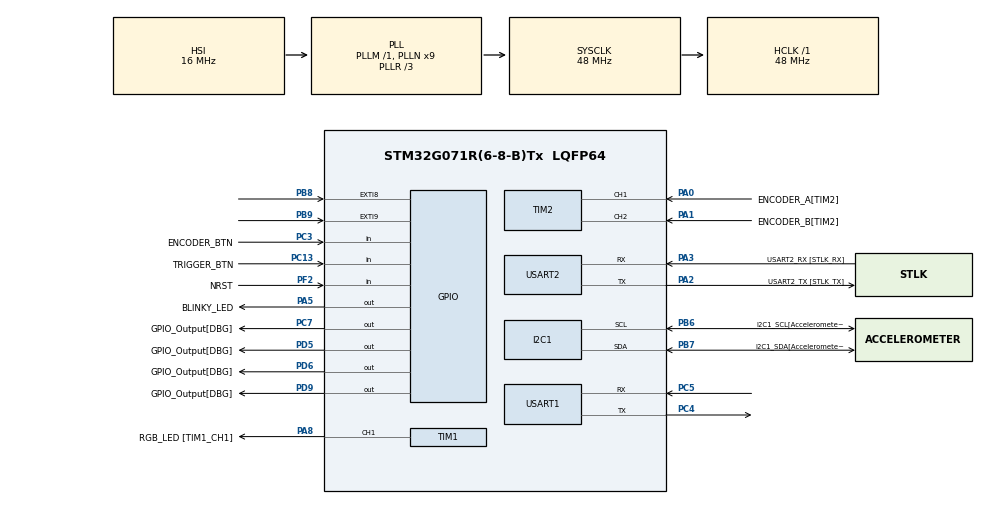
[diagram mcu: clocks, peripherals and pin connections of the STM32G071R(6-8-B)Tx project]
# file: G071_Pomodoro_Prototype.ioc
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Dma.Request0=TIM1_CH1
Dma.TIM1_CH1.0.Direction=DMA_MEMORY_TO_PERIPH
Dma.TIM1_CH1.0.EventEnable=DISABLE
Dma.TIM1_CH1.0.Instance=DMA1_Channel1
Dma.TIM1_CH1.0.MemDataAlignment=DMA_MDATAALIGN_HALFWORD
Dma.TIM1_CH1.0.MemInc=DMA_MINC_ENABLE
Dma.TIM1_CH1.0.Mode=DMA_NORMAL
Dma.TIM1_CH1.0.PeriphDataAlignment=DMA_PDATAALIGN_HALFWORD
Dma.TIM1_CH1.0.PeriphInc=DMA_PINC_DISABLE
Dma.TIM1_CH1.0.Polarity=HAL_DMAMUX_REQ_GEN_RISING
Dma.TIM1_CH1.0.Priority=DMA_PRIORITY_LOW
Dma.TIM1_CH1.0.RequestNumber=1
Dma.TIM1_CH1.0.SignalID=NONE
Dma.TIM1_CH1.0.SyncEnable=DISABLE
Dma.TIM1_CH1.0.SyncPolarity=HAL_DMAMUX_SYNC_NO_EVENT
Dma.TIM1_CH1.0.SyncRequestNumber=1
Dma.TIM1_CH1.0.SyncSignalID=NONE
I2C1.Timing=0x20303E5D
IWDG.Prescaler=IWDG_PRESCALER_32
Mcu.Family=STM32G0
Mcu.Name=STM32G071R(6-8-B)Tx
Mcu.Package=LQFP64
NVIC.DMA1_Channel1_IRQn=true\:0\:0\:false\:false\:true\:false\:true\:true
NVIC.TIM14_IRQn=true\:0\:0\:false\:false\:true\:true\:true\:true
PA0.GPIO_Label=ENCODER_A[TIM2]
PA0.Signal=S_TIM2_CH1_ETR
PA1.GPIO_Label=ENCODER_B[TIM2]
PA1.Signal=S_TIM2_CH2
PA13.GPIO_Label=SWDIO
PA13.Mode=Serial_Wire
PA13.Signal=SYS_SWDIO
PA14-BOOT0.GPIO_Label=SWCLK
PA14-BOOT0.Mode=Serial_Wire
PA14-BOOT0.Signal=SYS_SWCLK
PA2.GPIO_Label=USART2_TX [STLK_TX]
PA2.GPIO_PuPd=GPIO_PULLUP
PA2.Mode=Asynchronous
PA2.Signal=USART2_TX
PA3.GPIO_Label=USART2_RX [STLK_RX]
PA3.GPIO_PuPd=GPIO_PULLUP
PA3.Mode=Asynchronous
PA3.Signal=USART2_RX
PA5.GPIO_Label=BLINKY_LED
PA5.GPIO_Speed=GPIO_SPEED_FREQ_HIGH
PA5.Signal=GPIO_Output
PA8.GPIO_Label=RGB_LED [TIM1_CH1]
PA8.Signal=S_TIM1_CH1
PB6.GPIO_Label=I2C1_SCL[Accelerometer]
PB6.Mode=I2C
PB6.Signal=I2C1_SCL
PB7.GPIO_Label=I2C1_SDA[Accelerometer]
PB7.Mode=I2C
PB7.Signal=I2C1_SDA
PB8.Signal=GPXTI8
PB9.Signal=GPXTI9
PC13.GPIO_Label=TRIGGER_BTN
PC13.GPIO_PuPd=GPIO_PULLUP
PC13.Signal=GPIO_Input
PC3.GPIO_Label=ENCODER_BTN
PC3.GPIO_PuPd=GPIO_PULLUP
PC3.Signal=GPIO_Input
PC4.Mode=Asynchronous
PC4.Signal=USART1_TX
PC5.Mode=Asynchronous
PC5.Signal=USART1_RX
PC7.GPIO_Label=GPIO_Output[DBG]
PC7.Signal=GPIO_Output
PD5.GPIO_Label=GPIO_Output[DBG]
PD5.Signal=GPIO_Output
PD6.GPIO_Label=GPIO_Output[DBG]
PD6.Signal=GPIO_Output
PD9.GPIO_Label=GPIO_Output[DBG]
PD9.Signal=GPIO_Output
PF2\ -\ NRST.GPIO_Label=NRST
PF2\ -\ NRST.GPIO_PuPd=GPIO_PULLUP
PF2\ -\ NRST.Signal=GPIO_Input
ProjectManager.HeapSize=0x200
ProjectManager.StackSize=0x400
ProjectManager.TargetToolchain=STM32CubeIDE
RCC.ADCFreq_Value=48000000
RCC.AHBFreq_Value=48000000
RCC.CortexFreq_Value=48000000
RCC.EXTERNAL_CLOCK_VALUE=12288000
RCC.HCLKFreq_Value=48000000
RCC.HSE_VALUE=8000000
RCC.HSI_VALUE=16000000
RCC.LSE_VALUE=32768
RCC.PLLN=9
RCC.PLLR=RCC_PLLR_DIV3
RCC.SYSCLKFreq_VALUE=48000000
RCC.SYSCLKSource=RCC_SYSCLKSOURCE_PLLCLK
RCC.VCOOutputFreq_Value=144000000
RTC.Date=31
RTC.Hours=23
RTC.Minutes=59
RTC.Month=RTC_MONTH_DECEMBER
RTC.Seconds=40
SH.S_TIM1_CH1.0=TIM1_CH1,PWM Generation1 CH1
SH.S_TIM2_CH1_ETR.0=TIM2_CH1,Encoder_Interface
SH.S_TIM2_CH2.0=TIM2_CH2,Encoder_Interface
TIM1.Channel-PWM\ Generation1\ CH1=TIM_CHANNEL_1
TIM1.Period=60-1
TIM1.Prescaler=0
TIM14.Period=1000-1
TIM14.Prescaler=48-1
USART1.VirtualMode-Asynchronous=VM_ASYNC
USART2.VirtualMode-Asynchronous=VM_ASYNC
VP_IWDG_VS_IWDG.Mode=IWDG_Activate
VP_RTC_VS_RTC_Activate.Mode=RTC_Enabled
VP_RTC_VS_RTC_Calendar.Mode=RTC_Calendar
VP_SYS_VS_DBSignals.Mode=DisableDeadBatterySignals
VP_TIM14_VS_ClockSourceINT.Mode=Enable_Timer
VP_TIM1_VS_ClockSourceINT.Mode=Internal
board=NUCLEO-G071RB

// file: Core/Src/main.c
/* USER CODE BEGIN Header */
/**
 ******************************************************************************
 * @file           : main.c
 * @brief          : Main program body
 ******************************************************************************
 * @attention
 *
 * Copyright (c) 2023 STMicroelectronics.
 * All rights reserved.
 *
 * This software is licensed under terms that can be found in the LICENSE file
 * in the root directory of this software component.
 * If no LICENSE file comes with this software, it is provided AS-IS.
 *
 ******************************************************************************
 */
/* USER CODE END Header */
#include "main.h"
#include "dma.h"
#include "i2c.h"
#include "iwdg.h"
#include "rtc.h"
#include "tim.h"
#include "usart.h"
#include "gpio.h"

/* USER CODE BEGIN Includes */
#include "BlinkyLed.h"
#include "Common.h"
#include "Executer.h"
#include "Printf.h"

/* USER CODE END Includes */

void SystemClock_Config(void);

int main(void)
{

  /* MCU Configuration--------------------------------------------------------*/

  /* Reset of all peripherals, Initializes the Flash interface and the Systick. */
  HAL_Init();

  /* Configure the system clock */
  SystemClock_Config();

  /* Initialize all configured peripherals */
  MX_GPIO_Init();
  MX_DMA_Init();
  MX_USART2_UART_Init();
  MX_RTC_Init();
  MX_TIM1_Init();
  MX_TIM14_Init();
  MX_USART1_UART_Init();
  MX_TIM2_Init();
  MX_I2C1_Init();
  MX_IWDG_Init();
  /* USER CODE BEGIN 2 */
  HAL_TIM_Base_Start_IT(&htim14); // Timer for sampling TODO: move to the Button Handler
  Printf_SetUartPort(&huart2);

  Executer_run();

  /* USER CODE END 2 */

  /* Infinite loop */
  while (1)
  {

  }
}

void SystemClock_Config(void)
{
  RCC_OscInitTypeDef RCC_OscInitStruct = {0};
  RCC_ClkInitTypeDef RCC_ClkInitStruct = {0};

  /** Configure the main internal regulator output voltage
  */
  HAL_PWREx_ControlVoltageScaling(PWR_REGULATOR_VOLTAGE_SCALE1);

  /** Initializes the RCC Oscillators according to the specified parameters
  * in the RCC_OscInitTypeDef structure.
  */
  RCC_OscInitStruct.OscillatorType = RCC_OSCILLATORTYPE_HSI|RCC_OSCILLATORTYPE_LSI;
  RCC_OscInitStruct.HSIState = RCC_HSI_ON;
  RCC_OscInitStruct.HSIDiv = RCC_HSI_DIV1;
  RCC_OscInitStruct.HSICalibrationValue = RCC_HSICALIBRATION_DEFAULT;
  RCC_OscInitStruct.LSIState = RCC_LSI_ON;
  RCC_OscInitStruct.PLL.PLLState = RCC_PLL_ON;
  RCC_OscInitStruct.PLL.PLLSource = RCC_PLLSOURCE_HSI;
  RCC_OscInitStruct.PLL.PLLM = RCC_PLLM_DIV1;
  RCC_OscInitStruct.PLL.PLLN = 9;
  RCC_OscInitStruct.PLL.PLLP = RCC_PLLP_DIV2;
  RCC_OscInitStruct.PLL.PLLQ = RCC_PLLQ_DIV2;
  RCC_OscInitStruct.PLL.PLLR = RCC_PLLR_DIV3;
  if (HAL_RCC_OscConfig(&RCC_OscInitStruct) != HAL_OK)
  {
    Error_Handler();
  }

  /** Initializes the CPU, AHB and APB buses clocks
  */
  RCC_ClkInitStruct.ClockType = RCC_CLOCKTYPE_HCLK|RCC_CLOCKTYPE_SYSCLK
                              |RCC_CLOCKTYPE_PCLK1;
  RCC_ClkInitStruct.SYSCLKSource = RCC_SYSCLKSOURCE_PLLCLK;
  RCC_ClkInitStruct.AHBCLKDivider = RCC_SYSCLK_DIV1;
  RCC_ClkInitStruct.APB1CLKDivider = RCC_HCLK_DIV1;

  if (HAL_RCC_ClockConfig(&RCC_ClkInitStruct, FLASH_LATENCY_1) != HAL_OK)
  {
    Error_Handler();
  }
}

void Error_Handler(void)
{
  /* USER CODE BEGIN Error_Handler_Debug */
  /* User can add his own implementation to report the HAL error return state */
  __disable_irq();
  while (1)
  {
    BlinkyLed_toggle();
    HAL_Delay(100);
  }
  /* USER CODE END Error_Handler_Debug */
}

#ifdef  USE_FULL_ASSERT
/**
  * @brief  Reports the name of the source file and the source line number
  *         where the assert_param error has occurred.
  * @param  file: pointer to the source file name
  * @param  line: assert_param error line source number
  * @retval None
  */
void assert_failed(uint8_t *file, uint32_t line)
{
  /* USER CODE BEGIN 6 */
  /* User can add his own implementation to report the file name and line
     number, ex: printf("Wrong parameters value: file %s on line %d\r\n", file,
     line) */
  /* USER CODE END 6 */
}
#endif /* USE_FULL_ASSERT */
